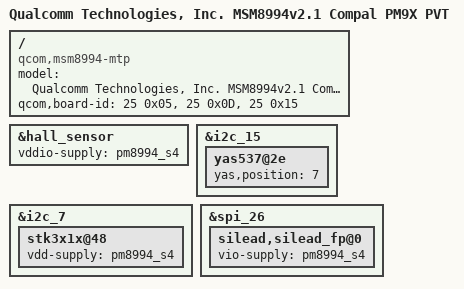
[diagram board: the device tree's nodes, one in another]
/* Copyright (c) 2014-2015, The Linux Foundation. All rights reserved.
 *
 * This program is free software; you can redistribute it and/or modify
 * it under the terms of the GNU General Public License version 2 and
 * only version 2 as published by the Free Software Foundation.
 *
 * This program is distributed in the hope that it will be useful,
 * but WITHOUT ANY WARRANTY; without even the implied warranty of
 * MERCHANTABILITY or FITNESS FOR A PARTICULAR PURPOSE.  See the
 * GNU General Public License for more details.
 */

/dts-v1/;

#include "msm8994-v2.1.dtsi"
#include "msm8994-pinctrl.dtsi"
#include "pm9x/msm8994-pm9x.dtsi"

/ {
	model = "Qualcomm Technologies, Inc. MSM8994v2.1 Compal PM9X PVT";
	compatible = "qcom,msm8994-mtp", "qcom,msm8994", "qcom,mtp";
	qcom,board-id = <25 0x05>, <25 0x0D>, <25 0x15>;
};

&hall_sensor {
	vddio-supply = <&pm8994_s4>;
};

&i2c_15 {
	yas537@2e {
		yas,position = <7>;
	};
};

&i2c_7 {
	stk3x1x@48 {
		vdd-supply = <&pm8994_s4>;
	};
};

&spi_26 {
	silead,silead_fp@0 {
		vio-supply = <&pm8994_s4>;
	};
};
